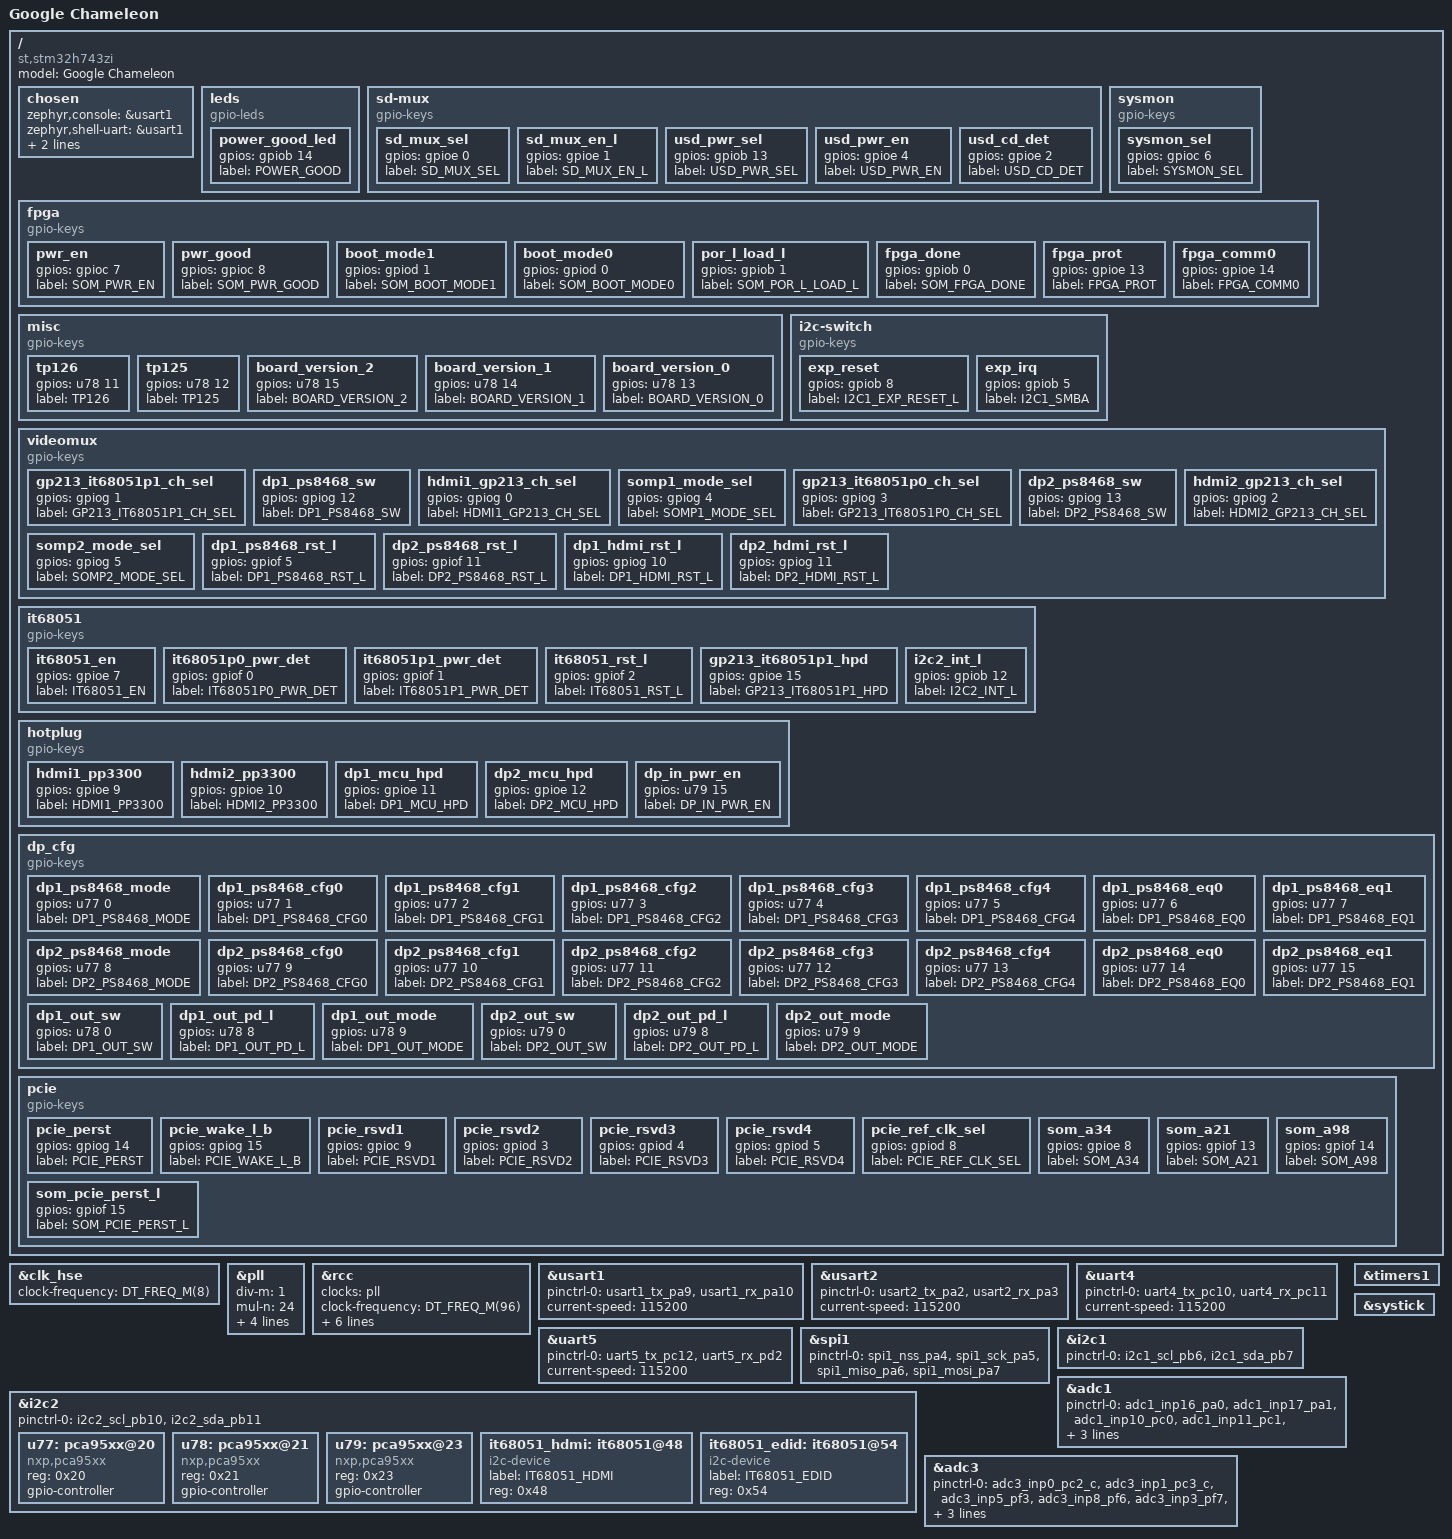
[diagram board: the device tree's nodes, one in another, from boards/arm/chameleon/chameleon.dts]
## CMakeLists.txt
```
# Copyright 2020 The ChromiumOS Authors
# Use of this source code is governed by a BSD-style license that can be
# found in the LICENSE file.
# SPDX-License-Identifier: BSD-3-Clause

cmake_minimum_required(VERSION 3.13.1)
set(BOARD_ROOT ${CMAKE_CURRENT_SOURCE_DIR} CACHE PATH "" FORCE)

if("${ZEPHYR_TOOLCHAIN_VARIANT}" STREQUAL "coreboot-sdk")
include_directories(toolchain/include)
endif()

# Use this copy of Pigweed
get_filename_component(PW_ROOT "${CMAKE_CURRENT_SOURCE_DIR}/../../../../third_party/pigweed" ABSOLUTE)
set(ENV{PW_ROOT} ${PW_ROOT})

set(dir_pw_third_party_nanopb "${CMAKE_CURRENT_SOURCE_DIR}/../../../../third_party/zephyr/nanopb" CACHE PATH "" FORCE)
set(pw_third_party_nanopb_ADD_SUBDIRECTORY ON CACHE BOOL "" FORCE)

list(APPEND ZEPHYR_EXTRA_MODULES
    ${PW_ROOT}
    ${dir_pw_third_party_nanopb}
)

find_package(Zephyr REQUIRED HINTS ${ZEPHYR_BASE})
project(chameleon)

add_definitions(-DCONFIG_RPC_BUFFER_SIZE=1024)
add_definitions(-DPW_LOG_LEVEL=PW_LOG_LEVEL_INFO)
add_definitions(-DPW_LOG_SHOW_MODULE=1)

# Define the proto library
include($ENV{PW_ROOT}/pw_protobuf_compiler/proto.cmake)
pw_proto_library(
    v3.protos
    SOURCES proto/v3.proto
    INPUTS proto/v3.options
)

add_custom_command(OUTPUT version.h
                   COMMAND ${CMAKE_CURRENT_SOURCE_DIR}/getversion.sh
                   WORKING_DIRECTORY ${CMAKE_CURRENT_SOURCE_DIR}/)
add_custom_target(getversion ALL DEPENDS version.h)

FILE(GLOB app_sources src/*.c src/*.cc)
target_include_directories(app PRIVATE include)
target_sources(app PRIVATE ${app_sources} )

zephyr_link_libraries(
    v3.protos.nanopb
    v3.protos.nanopb_rpc
)
```

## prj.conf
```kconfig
# Copyright 2020 The ChromiumOS Authors
# Use of this source code is governed by a BSD-style license that can be
# found in the LICENSE file.
#
# SPDX-License-Identifier: BSD-3-Clause

CONFIG_NEWLIB_LIBC=y
CONFIG_CPP=y
CONFIG_STD_CPP17=y
CONFIG_REQUIRES_FULL_LIBCPP=y

CONFIG_ASSERT=y

CONFIG_CBPRINTF_FP_SUPPORT=y
CONFIG_PRINTK=y
CONFIG_SHELL=y
CONFIG_SHELL_VT100_COLORS=n
CONFIG_SHELL_STATS=n
CONFIG_SHELL_PROMPT_UART="$ "
CONFIG_SHELL_CMD_BUFF_SIZE=1024

CONFIG_SERIAL=y
CONFIG_UART_INTERRUPT_DRIVEN=y
CONFIG_CONSOLE_SUBSYS=y
CONFIG_CONSOLE_GETCHAR=y

CONFIG_LOG=y
CONFIG_LOG_MODE_DEFERRED=y
CONFIG_LOG_SPEED=y
# default to write LOG_LEVEL_INF
CONFIG_LOG_DEFAULT_LEVEL=3

CONFIG_PINCTRL=y

CONFIG_NANOPB=y
CONFIG_PIGWEED_CHECKSUM=y
CONFIG_PIGWEED_HDLC_RPC=y
CONFIG_PIGWEED_ROUTER_PACKET_PARSER=y
CONFIG_PIGWEED_RPC_COMMON=y
CONFIG_PIGWEED_RPC_SERVER=y
CONFIG_PIGWEED_SYS_IO=y
CONFIG_PIGWEED_THREAD_SLEEP=y

# TODO: workaround for b/313926127
CONFIG_BOOT_DELAY=100
```

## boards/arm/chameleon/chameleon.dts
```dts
/* SPDX-License-Identifier: BSD-3-Clause
 *
 * Copyright 2020 The ChromiumOS Authors
 */

/dts-v1/;
#include <st/h7/stm32h743Xi.dtsi>
#include <st/h7/stm32h743zitx-pinctrl.dtsi>

/ {
	model = "Google Chameleon";
	compatible = "st,stm32h743zi", "st,stm32h743";

	chosen {
		zephyr,console = &usart1;
		zephyr,shell-uart = &usart1;
		zephyr,sram = &sram0;
		zephyr,flash = &flash0;
	};

	/*
	 * Note that the GPIO flags (the 0 at the end of the `gpios` tuple)
	 * are ignored by the I/O driver. All flags for GPIOs are specified
	 * in io.c.
	 */
	leds {
		compatible = "gpio-leds";
		power_good_led {
			gpios = <&gpiob 14 0>;
			label = "POWER_GOOD";
		};
	};

	sd-mux {
		compatible = "gpio-keys";

		sd_mux_sel {
			gpios = <&gpioe 0 0>;
			label = "SD_MUX_SEL";
		};

		sd_mux_en_l {
			gpios = <&gpioe 1 0>;
			label = "SD_MUX_EN_L";
		};

		usd_pwr_sel {
			gpios = <&gpiob 13 0>;
			label = "USD_PWR_SEL";
		};

		usd_pwr_en {
			gpios = <&gpioe 4 0>;
			label = "USD_PWR_EN";
		};

		usd_cd_det {
			gpios = <&gpioe 2 0>;
			label = "USD_CD_DET";
		};
	};

	sysmon {
		compatible = "gpio-keys";

		sysmon_sel {
			gpios = <&gpioc 6 0>;
			label = "SYSMON_SEL";
		};
	};

	fpga {
		compatible = "gpio-keys";

		pwr_en {
			gpios = <&gpioc 7 0>;
			label = "SOM_PWR_EN";
		};

		pwr_good {
			gpios = <&gpioc 8 0>;
			label = "SOM_PWR_GOOD";
		};

		boot_mode1 {
			gpios = <&gpiod 1 0>;
			label = "SOM_BOOT_MODE1";
		};

		boot_mode0 {
			gpios = <&gpiod 0 0>;
			label = "SOM_BOOT_MODE0";
		};

		por_l_load_l {
			gpios = <&gpiob 1 0>;
			label = "SOM_POR_L_LOAD_L";
		};

		fpga_done {
			gpios = <&gpiob 0 0>;
			label = "SOM_FPGA_DONE";
		};

		fpga_prot {
			gpios = <&gpioe 13 0>;
			label = "FPGA_PROT";
		};

		fpga_comm0 {
			gpios = <&gpioe 14 0>;
			label = "FPGA_COMM0";
		};
	};

	misc {
		compatible = "gpio-keys";

		tp126 {
			gpios = <&u78 11 0>;
			label = "TP126";
		};

		tp125 {
			gpios = <&u78 12 0>;
			label = "TP125";
		};

		board_version_2 {
			gpios = <&u78 15 0>;
			label = "BOARD_VERSION_2";
		};

		board_version_1 {
			gpios = <&u78 14 0>;
			label = "BOARD_VERSION_1";
		};

		board_version_0 {
			gpios = <&u78 13 0>;
			label = "BOARD_VERSION_0";
		};
	};

	i2c-switch {
		compatible = "gpio-keys";

		exp_reset {
			gpios = <&gpiob 8 0>;
			label = "I2C1_EXP_RESET_L";
		};

		exp_irq {
			gpios = <&gpiob 5 0>;
			label = "I2C1_SMBA";
		};
	};

	videomux {
		compatible = "gpio-keys";

		/*
		 * I/Os are initially set to so that none of the signals are
		 * connected to either the FPGA MGTs or the HDMI Receiver.
		 */
		gp213_it68051p1_ch_sel {
			/* GPU_SEL on U18 */
			gpios = <&gpiog 1 0>;
			label = "GP213_IT68051P1_CH_SEL";
		};

		dp1_ps8468_sw {
			/* SW on U3 */
			gpios = <&gpiog 12 0>;
			label = "DP1_PS8468_SW";
		};

		hdmi1_gp213_ch_sel {
			/* GPU_SEL on U10 */
			gpios = <&gpiog 0 0>;
			label = "HDMI1_GP213_CH_SEL";
		};

		somp1_mode_sel {
			/* GPU_SEL on U11 */
			gpios = <&gpiog 4 0>;
			label = "SOMP1_MODE_SEL";
		};

		/*
		 * Note that all of the channels are designated 1&2 except for
		 * the IT68051, which has ports 1 (channel 1 on the other
		 * switches) and 0 (channel 2 on the other switches).
		 */
		gp213_it68051p0_ch_sel {
			/* GPU_SEL on U31 */
			gpios = <&gpiog 3 0>;
			label = "GP213_IT68051P0_CH_SEL";
		};

		dp2_ps8468_sw {
			/* SW on U22 */
			gpios = <&gpiog 13 0>;
			label = "DP2_PS8468_SW";
		};

		hdmi2_gp213_ch_sel {
			/* GPU_SEL on U29 */
			gpios = <&gpiog 2 0>;
			label = "HDMI2_GP213_CH_SEL";
		};

		somp2_mode_sel {
			/* GPU_SEL on U14 */
			gpios = <&gpiog 5 0>;
			label = "SOMP2_MODE_SEL";
		};

		/*
		 * Reset lines for the PS8468 demuxes.
		 */
		dp1_ps8468_rst_l {
			/* RESETN on U3 */
			gpios = <&gpiof 5 0>;
			label = "DP1_PS8468_RST_L";
		};

		dp2_ps8468_rst_l {
			/* RESETN on U22 */
			gpios = <&gpiof 11 0>;
			label = "DP2_PS8468_RST_L";
		};

		/*
		 * Reset lines for the MCDP2900 DP->HDMI converters.
		 */
		dp1_hdmi_rst_l {
			/* EX_RESETN on U17 */
			gpios = <&gpiog 10 0>;
			label = "DP1_HDMI_RST_L";
		};

		dp2_hdmi_rst_l {
			/* EX_RESETN on U30 */
			gpios = <&gpiog 11 0>;
			label = "DP2_HDMI_RST_L";
		};
	};

	it68051 {
		compatible = "gpio-keys";

		it68051_en {
			gpios = <&gpioe 7 0>;
			label = "IT68051_EN";
		};

		it68051p0_pwr_det {
			gpios = <&gpiof 0 0>;
			label = "IT68051P0_PWR_DET";
		};

		it68051p1_pwr_det {
			gpios = <&gpiof 1 0>;
			label = "IT68051P1_PWR_DET";
		};

		it68051_rst_l {
			gpios = <&gpiof 2 0>;
			label = "IT68051_RST_L";
		};

		gp213_it68051p1_hpd {
			gpios = <&gpioe 15 0>;
			label = "GP213_IT68051P1_HPD";
		};

		i2c2_int_l {
			gpios = <&gpiob 12 0>;
			label = "I2C2_INT_L";
		};
	};

	hotplug {
		compatible = "gpio-keys";

		hdmi1_pp3300 {
			gpios = <&gpioe 9 0>;
			label = "HDMI1_PP3300";
		};

		hdmi2_pp3300 {
			gpios = <&gpioe 10 0>;
			label = "HDMI2_PP3300";
		};

		/*
		 * DP1 and DP2 HPD sense lines. There are two downstream HPD
		 * signals for the PS8468. When either one is asserted, the
		 * PS8468 wakes up and asserts its HPD_SRC. These GPIOs are
		 * connected to HPD_SRC, and let us know that the PS8468 is
		 * awake and we can configure the 8468 over the I2C bus.
		 */
		dp1_mcu_hpd {
			gpios = <&gpioe 11 0>;
			label = "DP1_MCU_HPD";
		};

		dp2_mcu_hpd {
			gpios = <&gpioe 12 0>;
			label = "DP2_MCU_HPD";
		};

		dp_in_pwr_en {
			gpios = <&u79 15 0>;
			label = "DP_IN_PWR_EN";
		};
	};

	dp_cfg {
		compatible = "gpio-keys";

		/*
		 * Most of these are GPIO_INPUT to allow the pull-up/pull-down
		 * resistors to apply the desired level. We only want to actively
		 * drive the MODE pins to select manual mux control by the SW pin.
		 */
		dp1_ps8468_mode {
			gpios = <&u77 0 0>;
			label = "DP1_PS8468_MODE";
		};

		dp1_ps8468_cfg0 {
			gpios = <&u77 1 0>;
			label = "DP1_PS8468_CFG0";
		};

		dp1_ps8468_cfg1 {
			gpios = <&u77 2 0>;
			label = "DP1_PS8468_CFG1";
		};

		dp1_ps8468_cfg2 {
			gpios = <&u77 3 0>;
			label = "DP1_PS8468_CFG2";
		};

		dp1_ps8468_cfg3 {
			gpios = <&u77 4 0>;
			label = "DP1_PS8468_CFG3";
		};

		dp1_ps8468_cfg4 {
			gpios = <&u77 5 0>;
			label = "DP1_PS8468_CFG4";
		};

		dp1_ps8468_eq0  {
			gpios = <&u77 6 0>;
			label = "DP1_PS8468_EQ0";
		};

		dp1_ps8468_eq1  {
			gpios = <&u77 7 0>;
			label = "DP1_PS8468_EQ1";
		};

		dp2_ps8468_mode {
			gpios = <&u77 8 0>;
			label = "DP2_PS8468_MODE";
		};

		dp2_ps8468_cfg0 {
			gpios = <&u77 9 0>;
			label = "DP2_PS8468_CFG0";
		};

		dp2_ps8468_cfg1 {
			gpios = <&u77 10 0>;
			label = "DP2_PS8468_CFG1";
		};

		dp2_ps8468_cfg2 {
			gpios = <&u77 11 0>;
			label = "DP2_PS8468_CFG2";
		};

		dp2_ps8468_cfg3 {
			gpios = <&u77 12 0>;
			label = "DP2_PS8468_CFG3";
		};

		dp2_ps8468_cfg4 {
			gpios = <&u77 13 0>;
			label = "DP2_PS8468_CFG4";
		};

		dp2_ps8468_eq0  {
			gpios = <&u77 14 0>;
			label = "DP2_PS8468_EQ0";
		};

		dp2_ps8468_eq1  {
			gpios = <&u77 15 0>;
			label = "DP2_PS8468_EQ1";
		};

		dp1_out_sw {
			gpios = <&u78 0 0>;
			label = "DP1_OUT_SW";
		};

		dp1_out_pd_l {
			gpios = <&u78 8 0>;
			label = "DP1_OUT_PD_L";
		};

		dp1_out_mode {
			gpios = <&u78 9 0>;
			label = "DP1_OUT_MODE";
		};

		dp2_out_sw {
			gpios = <&u79 0 0>;
			label = "DP2_OUT_SW";
		};

		dp2_out_pd_l {
			gpios = <&u79 8 0>;
			label = "DP2_OUT_PD_L";
		};

		dp2_out_mode {
			gpios = <&u79 9 0>;
			label = "DP2_OUT_MODE";
		};
	};

	pcie {
		compatible = "gpio-keys";

		pcie_perst {
			gpios = <&gpiog 14 0>;
			label = "PCIE_PERST";
		};

		pcie_wake_l_b {
			gpios = <&gpiog 15 0>;
			label = "PCIE_WAKE_L_B";
		};

		pcie_rsvd1 {
			gpios = <&gpioc 9 0>;
			label = "PCIE_RSVD1";
		};

		pcie_rsvd2 {
			gpios = <&gpiod 3 0>;
			label = "PCIE_RSVD2";
		};

		pcie_rsvd3 {
			gpios = <&gpiod 4 0>;
			label = "PCIE_RSVD3";
		};

		pcie_rsvd4 {
			gpios = <&gpiod 5 0>;
			label = "PCIE_RSVD4";
		};

		pcie_ref_clk_sel {
			gpios = <&gpiod 8 0>;
			label = "PCIE_REF_CLK_SEL";
		};

		som_a34 {
			gpios = <&gpioe 8 0>;
			label = "SOM_A34";
		};

		som_a21 {
			gpios = <&gpiof 13 0>;
			label = "SOM_A21";
		};

		som_a98 {
			gpios = <&gpiof 14 0>;
			label = "SOM_A98";
		};

		som_pcie_perst_l {
			gpios = <&gpiof 15 0>;
			label = "SOM_PCIE_PERST_L";
		};
	};
};

&clk_hse {
	clock-frequency = <DT_FREQ_M(8)>;
	status = "okay";
};

&pll {
	div-m = <1>;
	mul-n = <24>;
	div-p = <2>;
	div-q = <4>;
	div-r = <2>;
	clocks = <&clk_hse>;
	status = "okay";
};

&rcc {
	clocks = <&pll>;
	clock-frequency = <DT_FREQ_M(96)>;
	d1cpre = <1>;
	hpre = <1>;
	d1ppre = <2>;
	d2ppre1 = <2>;
	d2ppre2 = <2>;
	d3ppre = <2>;
};

&usart1 {
	pinctrl-0 = <&usart1_tx_pa9 &usart1_rx_pa10>;
	pinctrl-names = "default";
	current-speed = <115200>;
	status = "okay";
};

&usart2 {
	pinctrl-0 = <&usart2_tx_pa2 &usart2_rx_pa3>;
	pinctrl-names = "default";
	current-speed = <115200>;
	status = "okay";
};

&uart4 {
	pinctrl-0 = <&uart4_tx_pc10 &uart4_rx_pc11>;
	pinctrl-names = "default";
	current-speed = <115200>;
	status = "okay";
};

&uart5 {
	pinctrl-0 = <&uart5_tx_pc12 &uart5_rx_pd2>;
	pinctrl-names = "default";
	current-speed = <115200>;
	status = "okay";
};

&spi1 {
	pinctrl-0 = <&spi1_nss_pa4 &spi1_sck_pa5 &spi1_miso_pa6 &spi1_mosi_pa7>;
	pinctrl-names = "default";
	status = "okay";
};

&i2c1 {
	pinctrl-0 = <&i2c1_scl_pb6 &i2c1_sda_pb7>;
	pinctrl-names = "default";
	status = "okay";
};

&i2c2 {
	pinctrl-0 = <&i2c2_scl_pb10 &i2c2_sda_pb11>;
	pinctrl-names = "default";
	status = "okay";

	/* U77 I/O expander, config signals for PS8468 */
	u77: pca95xx@20 {
		compatible = "nxp,pca95xx";
		reg = <0x20>;
		#gpio-cells = <2>;
		gpio-controller;
	};

	/* U78 I/O expander, DP1 OUT config signals, plus misc I/O */
	u78: pca95xx@21 {
		compatible = "nxp,pca95xx";
		reg = <0x21>;
		#gpio-cells = <2>;
		gpio-controller;
	};

	/* U79 I/O expander DP2 OUT config, HDMI input reset, DP IN power */
	u79: pca95xx@23 {
		compatible = "nxp,pca95xx";
		reg = <0x23>;
		#gpio-cells = <2>;
		gpio-controller;
	};

	/* I2C address for the IT68051
	 *
	 * Note that the IT68051 documentation uses 8-bit addresses
	 * (ITE docs say that the HDMI block is address 0x90) but all of
	 * our code uses 7-bit addresses.
	 */
	it68051_hdmi: it68051@48 {
		compatible = "i2c-device";
		label = "IT68051_HDMI";
		reg = <0x48>;
	};

	it68051_edid: it68051@54 {
		compatible = "i2c-device";
		label = "IT68051_EDID";
		reg = <0x54>;
	};
};

&adc1 {
	pinctrl-0 = <&adc1_inp16_pa0 &adc1_inp17_pa1 &adc1_inp10_pc0
		     &adc1_inp11_pc1 &adc1_inp4_pc4 &adc1_inp8_pc5
		     &adc1_inp6_pf12>;
	pinctrl-names = "default";
	status = "okay";
	st,adc-clock-source = <SYNC>;
	st,adc-prescaler = <4>; /* 96MHz AHB / 4 = 24MHz */
};

&adc3 {
	/* These ADC inputs are only available on ADC3 */
	pinctrl-0 = <&adc3_inp0_pc2_c &adc3_inp1_pc3_c &adc3_inp5_pf3
		     &adc3_inp8_pf6 &adc3_inp3_pf7 &adc3_inp7_pf8
		     &adc3_inp2_pf9 &adc3_inp6_pf10>;
	pinctrl-names = "default";
	status = "okay";
	st,adc-clock-source = <SYNC>;
	st,adc-prescaler = <4>; /* 96MHz AHB / 4 = 24MHz */
};

&timers1 {
	status = "okay";
};

&systick {
	status = "okay";
};
```

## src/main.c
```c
/* SPDX-License-Identifier: BSD-3-Clause
 *
 * Copyright 2020 The ChromiumOS Authors
 * Use of this source code is governed by a BSD-style license that can be
 * found in the LICENSE file.
 */

#include <zephyr/kernel.h>
#include <zephyr/logging/log.h>

#include "io.h"

LOG_MODULE_REGISTER(main);

void main(void)
{
	int ret;

	ret = gpio_set_level(power_good_led, 1);
	if (ret < 0) {
		LOG_ERR("Failed to turn on POWER_GOOD, ret = %d.\n", ret);
	}
}
```

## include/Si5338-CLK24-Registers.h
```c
//Register map for use with AN428 (JumpStart)
//http://www.silabs.com/clocks
//#BEGIN_HEADER
//Date = Monday, January 10, 2022 5:41 PM
//File version = 3
//Software Name = ClockBuilder Pro
//Software version = 2.45.0.0
//Software date = 7 16, 2020
//Chip = Si533x
//Part Number = Si533x
//#END_HEADER
//Input Frequency (MHz) = 24.000000000
//Input Type = CMOS_SSTL_HSTL
//P1 = 1
//Input Mux = RefClk
//FDBK Input Frequency (MHz) = 24.000000000
//FDBK Input Type = OFF
//P2 = 1
//FDBK Mux = NoClk
//PFD Input Frequency (MHz) = 24.000000000
//VCO Frequency (GHz) = 2.700000
//N = 112  1/2  (112.5000)
//Internal feedback enabled
//Output Clock 0
// Output Frequency (MHz) = 100.000000000
// Mux Selection = IDn
// MultiSynth = 27  (27.0000)
// R = 1
//Output Clock 1
// Output Frequency (MHz) = 100.000000000
// Mux Selection = IDn
// MultiSynth = 27  (27.0000)
// R = 1
//Output Clock 2
// Output Frequency (MHz) = 100.000000000
// Mux Selection = IDn
// MultiSynth = 27  (27.0000)
// R = 1
//Output Clock 3
// Output Frequency (MHz) = 135.000000000
// Mux Selection = IDn
// MultiSynth = 20  (20.0000)
// R = 1
//Driver 0
// Enabled
// Powered on
// Output voltage = 3.30
// Output type = 3.3V LVDS
// Output state when disabled = AlwaysOn
//Driver 1
// Enabled
// Powered on
// Output voltage = 3.30
// Output type = 3.3V LVDS
// Output state when disabled = AlwaysOn
//Driver 2
// Enabled
// Powered on
// Output voltage = 1.80
// Output type = 1.8V CMOS on A
// Output state when disabled = AlwaysOn
//Driver 3
// Enabled
// Powered on
// Output voltage = 3.30
// Output type = 3.3V LVDS
// Output state when disabled = AlwaysOn
//Clock 0 phase inc/dec step size (ns) = 0.000
//Clock 1 phase inc/dec step size (ns) = 0.000
//Clock 2 phase inc/dec step size (ns) = 0.000
//Clock 3 phase inc/dec step size (ns) = 0.000
//Phase increment and decrement pin control is off
//Frequency increment and decrement pin control is off
//Frequency increment and decrement is disabled
//Initial phase offset 0 (ns) = 0.000
//Initial phase offset 1 (ns) = 0.000
//Initial phase offset 2 (ns) = 0.000
//Initial phase offset 3 (ns) = 0.000
//SSC is disabled

#ifdef __cplusplus
extern "C" {
#endif

#define NUM_REGS_MAX 350

typedef struct Reg_Data{
   unsigned char Reg_Addr;
   unsigned char Reg_Val;
   unsigned char Reg_Mask;
} Reg_Data;

Reg_Data const code Reg_Store[NUM_REGS_MAX] = {
{  0,0x00,0x00},
{  1,0x00,0x00},
{  2,0x00,0x00},
{  3,0x00,0x00},
{  4,0x00,0x00},
{  5,0x00,0x00},
{  6,0x00,0x1D},
{  7,0x00,0x00},
{  8,0x70,0x00},
{  9,0x0F,0x00},
{ 10,0x00,0x00},
{ 11,0x00,0x00},
{ 12,0x00,0x00},
{ 13,0x00,0x00},
{ 14,0x00,0x00},
{ 15,0x00,0x00},
{ 16,0x00,0x00},
{ 17,0x00,0x00},
{ 18,0x00,0x00},
{ 19,0x00,0x00},
{ 20,0x00,0x00},
{ 21,0x00,0x00},
{ 22,0x00,0x00},
{ 23,0x00,0x00},
{ 24,0x00,0x00},
{ 25,0x00,0x00},
{ 26,0x00,0x00},
{ 27,0x70,0x80},
{ 28,0x0B,0xFF},
{ 29,0x08,0xFF},
{ 30,0xB0,0xFF},
{ 31,0xC0,0xFF},
{ 32,0xC0,0xFF},
{ 33,0xC0,0xFF},
{ 34,0xC0,0xFF},
{ 35,0x20,0xFF},
{ 36,0x06,0x1F},
{ 37,0x06,0x1F},
{ 38,0x01,0x1F},
{ 39,0x06,0x1F},
{ 40,0x63,0xFF},
{ 41,0x54,0x7F},
{ 42,0x23,0x3F},
{ 43,0x00,0x00},
{ 44,0x00,0x00},
{ 45,0x00,0xFF},
{ 46,0x00,0xFF},
{ 47,0x14,0x3F},
{ 48,0x34,0xFF},
{ 49,0x00,0xFF},
{ 50,0xC3,0xFF},
{ 51,0x07,0xFF},
{ 52,0x10,0xFF},
{ 53,0x80,0xFF},
{ 54,0x0B,0xFF},
{ 55,0x00,0xFF},
{ 56,0x00,0xFF},
{ 57,0x00,0xFF},
{ 58,0x00,0xFF},
{ 59,0x01,0xFF},
{ 60,0x00,0xFF},
{ 61,0x00,0xFF},
{ 62,0x00,0x3F},
{ 63,0x10,0xFF},
{ 64,0x80,0xFF},
{ 65,0x0B,0xFF},
{ 66,0x00,0xFF},
{ 67,0x00,0xFF},
{ 68,0x00,0xFF},
{ 69,0x00,0xFF},
{ 70,0x01,0xFF},
{ 71,0x00,0xFF},
{ 72,0x00,0xFF},
{ 73,0x00,0x3F},
{ 74,0x10,0xFF},
{ 75,0x80,0xFF},
{ 76,0x0B,0xFF},
{ 77,0x00,0xFF},
{ 78,0x00,0xFF},
{ 79,0x00,0xFF},
{ 80,0x00,0xFF},
{ 81,0x01,0xFF},
{ 82,0x00,0xFF},
{ 83,0x00,0xFF},
{ 84,0x00,0x3F},
{ 85,0x10,0xFF},
{ 86,0x00,0xFF},
{ 87,0x08,0xFF},
{ 88,0x00,0xFF},
{ 89,0x00,0xFF},
{ 90,0x00,0xFF},
{ 91,0x00,0xFF},
{ 92,0x01,0xFF},
{ 93,0x00,0xFF},
{ 94,0x00,0xFF},
{ 95,0x00,0x3F},
{ 96,0x10,0x00},
{ 97,0x40,0xFF},
{ 98,0x36,0xFF},
{ 99,0x00,0xFF},
{100,0x00,0xFF},
{101,0x00,0xFF},
{102,0x00,0xFF},
{103,0x02,0xFF},
{104,0x00,0xFF},
{105,0x00,0xFF},
{106,0x80,0xBF},
{107,0x00,0xFF},
{108,0x00,0xFF},
{109,0x00,0xFF},
{110,0xC0,0xFF},
{111,0x00,0xFF},
{112,0x00,0xFF},
{113,0x00,0xFF},
{114,0xC0,0xFF},
{115,0x00,0xFF},
{116,0x80,0xFF},
{117,0x00,0xFF},
{118,0xC0,0xFF},
{119,0x00,0xFF},
{120,0x00,0xFF},
{121,0x00,0xFF},
{122,0xC0,0xFF},
{123,0x00,0xFF},
{124,0x00,0xFF},
{125,0x00,0xFF},
{126,0x00,0xFF},
{127,0x00,0xFF},
{128,0x00,0xFF},
{129,0x00,0x0F},
{130,0x00,0x0F},
{131,0x00,0xFF},
{132,0x00,0xFF},
{133,0x00,0xFF},
{134,0x00,0xFF},
{135,0x00,0xFF},
{136,0x00,0xFF},
{137,0x00,0xFF},
{138,0x00,0xFF},
{139,0x00,0xFF},
{140,0x00,0xFF},
{141,0x00,0xFF},
{142,0x00,0xFF},
{143,0x00,0xFF},
{144,0x00,0xFF},
{145,0x00,0x00},
{146,0xFF,0x00},
{147,0x00,0x00},
{148,0x00,0x00},
{149,0x00,0x00},
{150,0x00,0x00},
{151,0x00,0x00},
{152,0x00,0xFF},
{153,0x00,0xFF},
{154,0x00,0xFF},
{155,0x00,0xFF},
{156,0x00,0xFF},
{157,0x00,0xFF},
{158,0x00,0x0F},
{159,0x00,0x0F},
{160,0x00,0xFF},
{161,0x00,0xFF},
{162,0x00,0xFF},
{163,0x00,0xFF},
{164,0x00,0xFF},
{165,0x00,0xFF},
{166,0x00,0xFF},
{167,0x00,0xFF},
{168,0x00,0xFF},
{169,0x00,0xFF},
{170,0x00,0xFF},
{171,0x00,0xFF},
{172,0x00,0xFF},
{173,0x00,0xFF},
{174,0x00,0xFF},
{175,0x00,0xFF},
{176,0x00,0xFF},
{177,0x00,0xFF},
{178,0x00,0xFF},
{179,0x00,0xFF},
{180,0x00,0xFF},
{181,0x00,0x0F},
{182,0x00,0xFF},
{183,0x00,0xFF},
{184,0x00,0xFF},
{185,0x00,0xFF},
{186,0x00,0xFF},
{187,0x00,0xFF},
{188,0x00,0xFF},
{189,0x00,0xFF},
{190,0x00,0xFF},
{191,0x00,0xFF},
{192,0x00,0xFF},
{193,0x00,0xFF},
{194,0x00,0xFF},
{195,0x00,0xFF},
{196,0x00,0xFF},
{197,0x00,0xFF},
{198,0x00,0xFF},
{199,0x00,0xFF},
{200,0x00,0xFF},
{201,0x00,0xFF},
{202,0x00,0xFF},
{203,0x00,0x0F},
{204,0x00,0xFF},
{205,0x00,0xFF},
{206,0x00,0xFF},
{207,0x00,0xFF},
{208,0x00,0xFF},
{209,0x00,0xFF},
{210,0x00,0xFF},
{211,0x00,0xFF},
{212,0x00,0xFF},
{213,0x00,0xFF},
{214,0x00,0xFF},
{215,0x00,0xFF},
{216,0x00,0xFF},
{217,0x00,0xFF},
{218,0x00,0x00},
{219,0x00,0x00},
{220,0x00,0x00},
{221,0x0D,0x00},
{222,0x00,0x00},
{223,0x00,0x00},
{224,0xF4,0x00},
{225,0xF0,0x00},
{226,0x00,0x00},
{227,0x00,0x00},
{228,0x00,0x00},
{229,0x00,0x00},
{231,0x00,0x00},
{232,0x00,0x00},
{233,0x00,0x00},
{234,0x00,0x00},
{235,0x00,0x00},
{236,0x00,0x00},
{237,0x00,0x00},
{238,0x14,0x00},
{239,0x00,0x00},
{240,0x00,0x00},
{242,0x02,0x02},
{243,0xF0,0x00},
{244,0x00,0x00},
{245,0x00,0x00},
{247,0x00,0x00},
{248,0x00,0x00},
{249,0xA8,0x00},
{250,0x00,0x00},
{251,0x84,0x00},
{252,0x00,0x00},
{253,0x00,0x00},
{254,0x00,0x00},
{255, 1, 0xFF}, // set page bit to 1
{  0,0x00,0x00},
{  1,0x00,0x00},
{  2,0x00,0x00},
{  3,0x00,0x00},
{  4,0x00,0x00},
{  5,0x00,0x00},
{  6,0x00,0x00},
{  7,0x00,0x00},
{  8,0x00,0x00},
{  9,0x00,0x00},
{ 10,0x00,0x00},
{ 11,0x00,0x00},
{ 12,0x00,0x00},
{ 13,0x00,0x00},
{ 14,0x00,0x00},
{ 15,0x00,0x00},
{ 16,0x00,0x00},
{ 17,0x01,0x00},
{ 18,0x00,0x00},
{ 19,0x00,0x00},
{ 20,0x90,0x00},
{ 21,0x31,0x00},
{ 22,0x00,0x00},
{ 23,0x00,0x00},
{ 24,0x01,0x00},
{ 25,0x00,0x00},
{ 26,0x00,0x00},
{ 27,0x00,0x00},
{ 28,0x00,0x00},
{ 29,0x00,0x00},
{ 30,0x00,0x00},
{ 31,0x00,0xFF},
{ 32,0x00,0xFF},
{ 33,0x01,0xFF},
{ 34,0x00,0xFF},
{ 35,0x00,0xFF},
{ 36,0x90,0xFF},
{ 37,0x31,0xFF},
{ 38,0x00,0xFF},
{ 39,0x00,0xFF},
{ 40,0x01,0xFF},
{ 41,0x00,0xFF},
{ 42,0x00,0xFF},
{ 43,0x00,0x0F},
{ 44,0x00,0x00},
{ 45,0x00,0x00},
{ 46,0x00,0x00},
{ 47,0x00,0xFF},
{ 48,0x00,0xFF},
{ 49,0x01,0xFF},
{ 50,0x00,0xFF},
{ 51,0x00,0xFF},
{ 52,0x90,0xFF},
{ 53,0x31,0xFF},
{ 54,0x00,0xFF},
{ 55,0x00,0xFF},
{ 56,0x01,0xFF},
{ 57,0x00,0xFF},
{ 58,0x00,0xFF},
{ 59,0x00,0x0F},
{ 60,0x00,0x00},
{ 61,0x00,0x00},
{ 62,0x00,0x00},
{ 63,0x00,0xFF},
{ 64,0x00,0xFF},
{ 65,0x01,0xFF},
{ 66,0x00,0xFF},
{ 67,0x00,0xFF},
{ 68,0x90,0xFF},
{ 69,0x31,0xFF},
{ 70,0x00,0xFF},
{ 71,0x00,0xFF},
{ 72,0x01,0xFF},
{ 73,0x00,0xFF},
{ 74,0x00,0xFF},
{ 75,0x00,0x0F},
{ 76,0x00,0x00},
{ 77,0x00,0x00},
{ 78,0x00,0x00},
{ 79,0x00,0xFF},
{ 80,0x00,0xFF},
{ 81,0x00,0xFF},
{ 82,0x00,0xFF},
{ 83,0x00,0xFF},
{ 84,0x90,0xFF},
{ 85,0x31,0xFF},
{ 86,0x00,0xFF},
{ 87,0x00,0xFF},
{ 88,0x01,0xFF},
{ 89,0x00,0xFF},
{ 90,0x00,0xFF},
{ 91,0x00,0x0F},
{ 92,0x00,0x00},
{ 93,0x00,0x00},
{ 94,0x00,0x00},
{255, 0, 0xFF} }; // set page bit to 0
//End of file

#ifdef __cplusplus
}
#endif
```

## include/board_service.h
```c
/* SPDX-License-Identifier: BSD-3-Clause
 *
 * Copyright 2021 The ChromiumOS Authors
 * Use of this source code is governed by a BSD-style license that can be
 * found in the LICENSE file.
 *
 * Copied from the implementation stubs section of
 * build/v3.protos/nanopb_rpc/proto/v3.rpc.pb.h
 */

#ifndef __BOARD_SERVICE_H
#define __BOARD_SERVICE_H

#include "proto/v3.rpc.pb.h"

// Implementation class for board_service.
class board_service : public pw_rpc::nanopb::board_service::Service<board_service> {
 public:
  ::pw::Status get_board_version( const ::Empty& request, ::board_service_version_response& response);

  ::pw::Status get_sysmon( const ::Empty& request, ::sysmon_response& response);

  ::pw::Status get_source_presence( const ::Empty& request, ::source_presence_response& response);

  ::pw::Status get_code_version( const ::Empty& request, ::board_service_code_version_response& response);
};

#endif
```

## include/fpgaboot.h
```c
/* SPDX-License-Identifier: BSD-3-Clause
 *
 * Copyright 2020 The ChromiumOS Authors
 * Use of this source code is governed by a BSD-style license that can be
 * found in the LICENSE file.
 */

#ifndef __FPGABOOT_H
#define __FPGABOOT_H

#include <zephyr/kernel.h>

#ifdef __cplusplus
extern "C" {
#endif

/**
 * Define the boot source for the FPGA
 *
 * The Enclustra FPGA SOM (system-on-module) defines two pins, BOOT_MODE[1:0]
 * to control the boot source for the FPGA. The module includes an EMMC
 * flash (essentially an SD card in an IC package), and a quad-SPI flash
 * memory. The module also has SDIO signals that the carrier board can
 * route to an SD/microSD socket (which Chameleon v3 does).
 *
 * @note The default boot mode on Chameleon v3 is SDIO.
 */
enum fpga_boot_mode { FPGA_BOOT_EMMC, FPGA_BOOT_QSPI, FPGA_BOOT_SDIO };

/*
 * @brief Set the boot mode for the FPGA SOM
 *
 * @param mode One of the `fpga_boot_mode` values
 * @retval 0
 * No errors.
 * @retval -EINVAL
 * Invalid value, probably from passing an int instead of enum
 */
int fpgaboot_set_boot_mode(enum fpga_boot_mode mode);

/*
 * @brief Send a request to power on
 *
 * @note The caller should call `fpgaboot_set_boot_mode` before this unless
 * they want to use the default value (which is `FPGA_BOOT_SDIO`)
 *
 * @retval 0
 * No errors.
 * @retval -ENOMSG
 * Message was not posted.
 * @retval -EAGAIN
 * Waiting period timed out.
 */
int fpgaboot_power_on(void);

/*
 * @brief Send a request to power off
 *
 * @retval 0
 * No errors.
 * @retval -ENOMSG
 * Message was not posted.
 * @retval -EAGAIN
 * Waiting period timed out.
 */
int fpgaboot_power_off(void);

#ifdef __cplusplus
}
#endif

#endif
```

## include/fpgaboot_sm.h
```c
/* SPDX-License-Identifier: BSD-3-Clause
 *
 * Copyright 2020 The ChromiumOS Authors
 * Use of this source code is governed by a BSD-style license that can be
 * found in the LICENSE file.
 *
 * Implement a state machine for powering on, booting, and powering off the
 * FPGA System-on-Module (SOM) that is the heart of Chameleon v3.
 * See doc/fpga_sm.md for design details.
 */

#ifndef __FPGABOOT_SM_H
#define __FPGABOOT_SM_H

#include <stdbool.h>
#include <zephyr/kernel.h>

#ifdef __cplusplus
extern "C" {
#endif

enum fpga_state {
	FPGABOOT_OFF,
	FPGABOOT_PWR_GOOD,
	FPGABOOT_LOAD,
	FPGABOOT_RUNNING,
};

enum fpga_event {
	FPGABOOT_EVENT_NONE,
	FPGABOOT_POWER_ON_REQ,
	FPGABOOT_POWER_OFF_REQ,
	FPGABOOT_SOM_PWR_GOOD_ASSERTED,
	FPGABOOT_SOM_PWR_GOOD_DEASSERTED,
	FPGABOOT_SOM_FPGA_DONE_ASSERTED,
	FPGABOOT_SOM_FPGA_DONE_DEASSERTED,
	FPGABOOT_TIMER_EXPIRED,
};

#define FPGABOOT_ACTION_NONE 0x00
#define FPGABOOT_ASSERT_SOM_PWR_EN 0x01
#define FPGABOOT_DEASSERT_SOM_PWR_EN 0x02
/* NB: SOM_POR_L_LOAD_L is active low, so "assert" == "set to 0V" */
#define FPGABOOT_ASSERT_SOM_POR_L_LOAD_L 0x04
#define FPGABOOT_DEASSERT_SOM_POR_L_LOAD_L 0x08
#define FPGABOOT_START_SHORT_TIMER 0x10
#define FPGABOOT_START_LONG_TIMER 0x20
#define FPGABOOT_STOP_TIMER 0x40

/**
 * @brief Initialize the state machine data
 *
 * Uses the values of `PWR_EN`, `PWR_GOOD`, and `FPGA_DONE` to determine
 * which state it should go to.
 *
 * @param pwr_en
 * @param pwr_good
 * @param fpga_done
 * @param p_state pointer to an `fpga_state` variable
 * @param[out] p_actions pointer to variable to set bit flags for actions.
 */
void fpgaboot_init_state_machine(int pwr_en, int pwr_good, int fpga_done,
                                 enum fpga_state *p_state, uint32_t *p_actions);

/**
 * @brief Run the state machine
 *
 * The caller should set `event` to indicate the event being processed.
 * The state machine may change `*p_state` and set one or more bits in
 * `*p_actions` to indicate what the caller should do next.
 *
 * @param event the event being processed
 * @param[inout] p_state pointer to an `fpga_state` variable
 * @param[out] p_actions pointer to variable to set bit flags for actions.
 */
void fpgaboot_run_state_machine(enum fpga_event event, enum fpga_state *p_state,
				uint32_t *p_actions);

/**
 * @brief Determine if the FPGA is in a steady state, on or off
 *
 * @param state an `fpga_state` variable
 * @retval true
 * if the FPGA is either on or off
 * @retval false
 * if the FPGA is in a different state moving towards either on or off
 */
bool fpgaboot_is_steady_state(enum fpga_state state);

#ifdef __cplusplus
}
#endif

#endif
```

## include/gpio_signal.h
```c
/* SPDX-License-Identifier: BSD-3-Clause
 *
 * Copyright 2020 The Chromium OS Authors. All rights reserved.
 * Use of this source code is governed by a BSD-style license that can be
 * found in the LICENSE file.
 */

#ifndef __GPIO_SIGNAL_H
#define __GPIO_SIGNAL_H

#include <zephyr.h>
#include <device.h>
#include <devicetree.h>
#include <init.h>
#include <drivers/gpio.h>

#define GPIO_PIN_WITH_COMMA(path) DT_GPIO_PIN(path, gpios),

#define GPIO_FLAGS_WITH_COMMA(path) DT_GPIO_FLAGS(path, gpios),

#define NULL_WITH_COMMA(path) NULL,

#define GPIO_DEV_NAME_WITH_COMMA(path) DT_GPIO_LABEL(path, gpios),

#define GPIO_ENUM(path) DT_CAT(GPIO_, path)
#define GPIO_ENUM_WITH_COMMA(path) GPIO_ENUM(path),

#define DECLARE_GPIOS_FOR(path)                                               \
	static const gpio_pin_t gpio_pins[] = { DT_FOREACH_CHILD(             \
		DT_PATH(path), GPIO_PIN_WITH_COMMA) };                        \
	static const int gpio_flags[] = { DT_FOREACH_CHILD(                   \
		DT_PATH(path), GPIO_FLAGS_WITH_COMMA) };                      \
	static const struct device *gpio_devs[] = { DT_FOREACH_CHILD(         \
		DT_PATH(path), NULL_WITH_COMMA) };                            \
	static const char *const gpio_dev_names[] = { DT_FOREACH_CHILD(       \
		DT_PATH(path), GPIO_DEV_NAME_WITH_COMMA) };                   \
	enum { DT_FOREACH_CHILD(DT_PATH(path), GPIO_ENUM_WITH_COMMA) };       \
	static int local_init_devices_for_##path(const struct device *ptr)    \
	{                                                                     \
		ARG_UNUSED(ptr);                                              \
		for (int idx = 0; idx < ARRAY_SIZE(gpio_devs); ++idx) {       \
			gpio_devs[idx] =                                      \
				device_get_binding(gpio_dev_names[idx]);      \
			if (!gpio_devs[idx]) {                                \
				printk("local_init_devices_for_%s: "          \
				       "device_get_binding(%s) failed!\n",    \
				       #path, gpio_dev_names[idx]);           \
				continue;                                     \
			}                                                     \
			int ret = gpio_pin_configure(gpio_devs[idx],          \
						     gpio_pins[idx],          \
						     gpio_flags[idx]);        \
			if (ret != 0) {                                       \
				printk("local_init_devices_for_%s: "          \
				       "gpio_pin_configure(%s, %d, %d) "      \
				       "failed, ret = %d\n",                  \
				       #path, gpio_dev_names[idx],            \
				       gpio_pins[idx], gpio_flags[idx], ret); \
				continue;                                     \
			}                                                     \
		}                                                             \
		return 0;                                                     \
	}                                                                     \
	SYS_INIT(local_init_devices_for_##path, APPLICATION, 1);

#define GPIO_LOOKUP_COMMON(path) \
	gpio_devs[GPIO_ENUM(path)], gpio_pins[GPIO_ENUM(path)]
#define GPIO_LOOKUP(...) GPIO_LOOKUP_COMMON(DT_PATH(__VA_ARGS__))

/*
 * In your C file, include this header and declare the GPIOs based on the
 * devicetree node.
 *
 *  #include "gpio_signal.h"
 *  DECLARE_GPIOS_FOR(sd_mux);
 *
 * This macro declares some static const arrays and a local function (called
 * from SYS_INIT) that will initialize all of the GPIOs.
 *
 * Use `GPIO_LOOKUP(sd_mux, sd_mux_sel)` anywhere you need a `struct device*`
 * and a `gpio_pin_t` together:
 *
 *  gpio_pin_set(GPIO_LOOKUP(sd_mux, sd_mux_sel), value);
 *  gpio_pin_get(GPIO_LOOKUP(sd_mux, sd_mux_sel));
 *
 * Use `GPIO_ENUM(DT_PATH(...))` if you need the `struct device*` or the
 * `gpio_pin_t` separately, such as for setting up interrupt handlers:
 *
 *  gpio_init_callback(&pwr_good_cb_data, pwr_good_cb,
 *                     BIT(gpio_pins[GPIO_ENUM(DT_PATH(fpga, pwr_good))]));
 *  gpio_add_callback(gpio_devs[GPIO_ENUM(DT_PATH(fpga, pwr_good))],
 *                    &pwr_good_cb_data);
 *
 */

#endif
```

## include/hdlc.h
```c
/* SPDX-License-Identifier: BSD-3-Clause
 *
 * Copyright 2023 The ChromiumOS Authors
 * Use of this source code is governed by a BSD-style license that can be
 * found in the LICENSE file.
 */

#ifndef __HDLC_H
#define __HDLC_H

#include <zephyr/kernel.h>
#include <zephyr/drivers/uart.h>
#include <zephyr/logging/log.h>

#include "pw_hdlc/rpc_channel.h"
#include "pw_rpc/server.h"
#include "pw_status/status.h"
#include "pw_stream/sys_io_stream.h"

extern pw::stream::SysIoWriter hdlc_writer;
extern k_mutex hdlc_uart_mutex;

#endif /* __HDLC_H */
```

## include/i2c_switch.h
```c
/* SPDX-License-Identifier: BSD-3-Clause
 *
 * Copyright 2020 The ChromiumOS Authors
 * Use of this source code is governed by a BSD-style license that can be
 * found in the LICENSE file.
 */

#ifndef __I2C_SWITCH_H
#define __I2C_SWITCH_H

#include <zephyr/kernel.h>

#ifdef __cplusplus
extern "C" {
#endif

enum i2c_switch_reset_value {
	RESET_ASSERTED = 0,
	RESET_DEASSERTED
};

/**
 * @brief Select which bus is enabled
 *
 * The I2C switch controls access to 4 secondary buses. Any task that sets
 * the switch to enable a secondary bus expects to have exclusive access
 * to the bus until it's done. Allowing another task to come along and change
 * the switch to enable a different bus will cause problems. So ... setting
 * the switch to enable a secondary bus will also lock a mutex (or wait for
 * the mutex if it's already locked). Setting the switch to "disabled" will
 * unlock the mutex.
 *
 * @param bus bus number, 0-3, of which bus to enable. Any number <0 or >3
 * will disable all buses.
 *
 * @retval 0 if successful.
 * @retval -ENODEV or error return from Zephyr API functions.
 */
int i2c_switch_select_bus(int bus);

/**
 * @brief Control the reset pin on the i2c switch.
 *
 * @param val one of enum i2c_switch_reset_value to assert or deassert the
 * reset pin
 *
 * @retval 0 if successful.
 * @retval -ENODEV or error return from Zephyr API functions.
 */
int i2c_switch_reset(enum i2c_switch_reset_value val);

/**
 * @brief Return interrupt status register
 *
 * The MAX7367 interrupt status indicates which of the downstream interrupt
 * lines are asserted. Reading the interrupt status does not clear it; the
 * downstream devices have to de-assert their interrupt lines.
 *
 * @note The only interrupt line connected to anything other than a pull-up
 * is `I2C1_EXP_INT2_L`, and only the EP91A6SQ chips are connected to it.
 *
 * @retval
 * -EIO General input / output error.
 * @retval
 * bitfield where bit 0 is set for INT0, bit 1 set for INT1, etc.
 */
int i2c_switch_get_int_status(void);

#ifdef __cplusplus
}
#endif

#endif
```

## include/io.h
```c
/* SPDX-License-Identifier: BSD-3-Clause
 *
 * Copyright 2021 The Chromium OS Authors. All rights reserved.
 * Use of this source code is governed by a BSD-style license that can be
 * found in the LICENSE file.
 */

#ifndef __IO_H
#define __IO_H

#include <zephyr/kernel.h>
#include <zephyr/drivers/gpio.h>

#ifdef __cplusplus
extern "C" {
#endif

enum gpio_signal {
	power_good_led,
	sd_mux_sel,
	sd_mux_en_l,
	usd_pwr_sel,
	usd_pwr_en,
	usd_cd_det,
	sysmon_sel,
	pwr_en,
	pwr_good,
	boot_mode1,
	boot_mode0,
	por_l_load_l,
	fpga_done,
	fpga_prot,
	fpga_comm0,
	tp126,
	tp125,
	board_version_2,
	board_version_1,
	board_version_0,
	si5338c_int,
	exp_reset,
	exp_irq,
	gp213_it68051p1_ch_sel,
	dp1_ps8468_sw,
	hdmi1_gp213_ch_sel,
	somp1_mode_sel,
	gp213_it68051p0_ch_sel,
	dp2_ps8468_sw,
	hdmi2_gp213_ch_sel,
	somp2_mode_sel,
	dp1_ps8468_rst_l,
	dp2_ps8468_rst_l,
	dp1_hdmi_rst_l,
	dp2_hdmi_rst_l,
	it68051_en,
	it68051p0_pwr_det,
	it68051p1_pwr_det,
	it68051_rst_l,
	gp213_it68051p1_hpd,
	i2c2_int_l,
	dp1_auxp_det,
	dp1_auxn_det,
	dp2_auxp_det,
	dp2_auxn_det,
	hdmi1_pp3300,
	hdmi2_pp3300,
	dp1_mcu_hpd,
	dp2_mcu_hpd,
	dp_in_pwr_en,
	dp1_ps8468_mode,
	dp1_ps8468_cfg0,
	dp1_ps8468_cfg1,
	dp1_ps8468_cfg2,
	dp1_ps8468_cfg3,
	dp1_ps8468_cfg4,
	dp1_ps8468_eq0,
	dp1_ps8468_eq1,
	dp2_ps8468_mode,
	dp2_ps8468_cfg0,
	dp2_ps8468_cfg1,
	dp2_ps8468_cfg2,
	dp2_ps8468_cfg3,
	dp2_ps8468_cfg4,
	dp2_ps8468_eq0,
	dp2_ps8468_eq1,
	dp1_out_sw,
	dp1_out_pd_l,
	dp1_out_mode,
	dp2_out_sw,
	dp2_out_pd_l,
	dp2_out_mode,
	pcie_perst_l,
	pcie_wake_l,
	pcie_rsvd1,
	pcie_rsvd2,
	pcie_rsvd3,
	pcie_rsvd4,
	som_a34,
	som_a21,
	som_a98,
	som_a104,
};

/**
 * @brief Get the current value of a signal.
 *
 * @param signal	Signal to get
 * @return 0 if low, 1 if high.
 */
int gpio_get_level(enum gpio_signal signal);

/**
 * @brief Set the value of a signal.
 *
 * @param signal	Signal to set
 * @param value		New value for signal (0 = low, 1 = high)
 * @return 0 if successful, otherwise errno from gpio_pin_set
 */
int gpio_set_level(enum gpio_signal signal, int value);

/**
 * @brief Return the device pointer of a given GPIO signal.
 *
 * This allows code to use other Zephyr API calls such as configuring
 * for interrupts.
 *
 * @param signal    Signal to name
 * @returns device pointer for the GPIO
 */
const struct device *gpio_get_device(enum gpio_signal signal);

/**
 * Return the pin number of a given GPIO signal.
 *
 * This allows code to use other Zephyr API calls such as configuring
 * for interrupts.
 *
 * @param signal    Signal to name
 * @returns pin number for the GPIO
 */
gpio_pin_t gpio_get_pin(enum gpio_signal signal);

#ifdef __cplusplus
}
#endif

#endif
```

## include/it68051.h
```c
/* SPDX-License-Identifier: BSD-3-Clause
 *
 * Copyright 2020 The ChromiumOS Authors
 * Use of this source code is governed by a BSD-style license that can be
 * found in the LICENSE file.
 *
 * "Public" API for controling the IT68051 HDMI Receiver.
 */

#ifndef __IT68051_H
#define __IT68051_H

#include <zephyr/kernel.h>

#ifdef __cplusplus
extern "C" {
#endif

/*
 * Note that the HDMI/DP ports are connected to the IT68051 as HDMI1/DP1 to
 * IT68051 Port 1, and HDMI2/DP2 are connected to IT68051 Port **zero**.
 */
enum it68051_port { PORT1 = 1, PORT2 = 0 };

enum pixel_mode { MODE_SINGLE = 0, MODE_DUAL = 1 };

enum avi_color_format {
	COLOR_FORMAT_RGB = 0,
	COLOR_FORMAT_YUV422 = 1,
	COLOR_FORMAT_YUV444 = 2,
	COLOR_FORMAT_YUV420 = 3,
	COLOR_FORMAT_BYPASS_CSC = 4
};

enum avi_colorimetry {
	COLORIMETRY_UNKNOWN,
	COLORIMETRY_ITU601 = 1,
	COLORIMETRY_ITU709 = 2,
	COLORIMETRY_EXTEND = 3
};

enum avi_range_type_rgb {
	RGB_RANGE_DEPENDED_ON_VIC = 0,
	RGB_RANGE_LIMIT = 1,
	RGB_RANGE_FULL = 2,
	RGB_RANGE_RESERVE
};

enum avi_range_type_yuv {
	YUV_RANGE_LIMIT = 0,
	YUV_RANGE_FULL = 1,
	YUV_RANGE_RESERVE1,
	YUV_RANGE_RESERVE2
};

enum video_data_path {
	TTL_SDR = 0,
	TTL_DDR,
	TTL_HALF_BUS_DDR,
	TTL_SDR_BTA1004,
	TTL_DDR_BTA1004
};

enum video_sync_mode {
	TTL_SEP_SYNC = 0,
	TTL_EMB_SYNC,
};

/* Details about the video timing */
struct vtiming {
	uint16_t h_active;
	uint16_t v_active;
	uint16_t h_total;
	uint16_t v_total;
	uint32_t pclk;
	uint32_t tmdsclk;
	uint32_t frame_rate;
	uint16_t h_front_porch;
	uint16_t h_sync_width;
	uint16_t h_back_porch;
	uint16_t v_front_porch;
	uint16_t v_sync_width;
	uint16_t v_back_porch;
	uint16_t scan_mode;
	uint16_t v_polarity;
	uint16_t h_polarity;
	uint32_t n;
	uint32_t cts;
};

/* Details about the audio timing */
struct atiming {
	bool aud_3d_on;
	bool mult_aud_on;
	bool hbr_aud;
	bool dsd_aud;

	/* Can be -1 if invalid */
	int8_t aud_ch;

	/* Fs in Hz, except
	 * 0 = "Refer to Stream Header"
	 * -1 = Invalid
	 */
	int32_t aud_fs;
};

/* Details from the AVI Information Frame */
struct aviif {
	enum avi_color_format aviif_input_color_format;
	enum avi_colorimetry aviif_colorimetry;
	enum avi_range_type_rgb aviif_rgb_quantization_range;
	enum avi_range_type_yuv aviif_yuv_quantization_range;
	uint8_t aviif_vic;
	uint8_t aviif_extended_colorimetry;
};

/**
 * @brief Get the chip ID
 *
 * Several functions depend on the specific silicon version to determine
 * which registers to write and what values to write.
 *
 * @return Chip ID byte
 */
uint8_t it68051_get_chip_id(void);

/**
 * @brief Configure how the decoded video is presented on the output bus
 *
 * Configure the data path (SDR or DDR plus variations), whether sync signals
 * are on separate pins or embedded in the data, and the color format
 * (RGB or a couple of YUV options).
 *
 * Based on code in iTE6805_Set_TTL_Video_Path in iTE6805_DRV.c
 *
 * @param video_out_data_path signalling on the TTL lines
 * @param video_sync_mode if sync is separate or embedded
 * @param output_color_format RGB or YUV format, with possible decimation for
 * YUV format
 */
void it68051_set_ttl_video_path(enum video_data_path video_out_data_path,
				enum video_sync_mode video_sync_mode,
				enum avi_color_format output_color_format);

/**
 * @brief Calculate all kinds of data about the input video stream
 *
 * Based on code in iTE6805_Get_VID_Info in iTE6805_DRV.c
 *
 * @param vt pointer to a struct vtiming to fill in
 */
void it68051_get_vid_info(struct vtiming *vt);

/**
 * @brief Calculate all kinds of data about the input audio stream
 *
 * Based on code in iTE6805_Show_AUD_Info in iTE6805_DRV.c
 *
 * @param at pointer to a struct atiming to fill in
 */
void it68051_get_aud_info(struct atiming *at);

/**
 * @brief Get information from the AVI Information Frame
 *
 * @param if pointer to a struct to fill in
 */
void it68051_get_aviif(struct aviif *info);

/**
 * @brief Determine if the TTL outputs are in single- or dual-pixel mode
 *
 * Based on code in iTE6805_Check_Single_Dual_Mode in iTE6805_DRV.c
 *
 * @return MODE_DUAL or MODE_SINGLE to indicate the pixel mode
 */
enum pixel_mode it68051_get_pixel_mode(void);

/**
 * @brief Set the TTL outputs for single- or dual-pixel mode
 *
 * This function sets an internal flag that `it68051_video_output_setting`
 * uses to write the correct value to the register. So this function
 * is not exactly orthogonal to `it68051_get_pixel_mode`.
 *
 * @param mode MODE_DUAL or MODE_SINGLE
 */
void it68051_set_pixel_mode(enum pixel_mode mode);

/**
 * @brief Query if the link status is active
 *
 * This function just returns the internal variable `vid_stable_done`
 * to indicate if we have an established video link on the IT68051.
 *
 * @return bool indicating if the link is active
 */
bool it68051_get_link_active(void);

/**
 * @brief Control whether the video output pins are tristated
 *
 * @param is_tristate true to tristate the pins, false to actively drive them
 *
 * Based on code in iTE6805_Set_Video_Tristate in iTE6805_DRV.c
 */
void it68051_set_video_tristate(bool is_tristate);

/**
 * @brief Control whether the audio output pins are tristated
 *
 * @param is_tristate true to tristate the pins, false to actively drive them
 *
 * Based on code in iTE6805_Set_Audio_Tristate in iTE6805_DRV.c
 */
void it68051_set_audio_tristate(bool is_tristate);

/**
 * @brief Control the HPD (hot plug detect) signals for both ports
 *
 * HDMI uses a HPD (hot plug detect) signal to indicate that a cable is
 * connected. The sink (that's us) has to assert HPD for the source (that's
 * the Chromebook) to recognize a connected sink, query the EDID, and then
 * start sending data to it.
 *
 * Based on code in iTE6805_Set_HPD_Ctrl and iTE6805_Port_Select_Body in
 * iTE6805_DRV.c
 *
 * b/201944380, when setting HPD low, also pulse the EXT_RESET_N signal
 * for the MCDP2900 DisplayPort to HDMI converter chip. This chip keeps its
 * HPD output asserted, even when the HPD input is de-asserted, and the only
 * way we've found to get HPD to de-assert is to reset the chip. The MCDP2900
 * datasheet is unclear on how long the external reset pulse needs to be
 * (rev H datasheet, figure 4), so we're using a 2ms delay between asserting
 * the reset and releasing it.
 *
 * @param port PORT1 or PORT2
 * @param hpd_state false to de-assert, true to assert
 */
void it68051_set_hpd(enum it68051_port port, bool hpd_state);

/**
 * @brief Query the HPD (hot plug detect) signals for both ports
 *
 * Determine if we are driving HPD on the port.
 *
 * @param port PORT1 or PORT2
 * @return Whether HPD is being asserted
 */
bool it68051_get_hpd(enum it68051_port port);

/**
 * @brief Select which port the HDMI receiver is listening to
 *
 * The IT68051 has two input ports, so we need to tell it which port it
 * should be decoding.
 *
 * Based on code in iTE6805_Port_Select in iTE6805_SYS.c
 *
 * @param port PORT1 or PORT2
 */
void it68051_port_select(enum it68051_port port);

/**
 * @brief Determine  which port the HDMI receiver is listening to
 *
 * @return PORT1 or PORT2
 */
enum it68051_port it68051_get_selected_port(void);

/**
 * @brief Determine if the PWR_DET signal is active for a port
 *
 * Note that since these are controlled by the STM32, they will almost
 * always be active. "almost always"
 * Also, with an HDMI connector, the signal is 5V, but the R0PWR5V and R1PWR5V
 * pins are 3.3V logic/5V tolerant, so the 3.3V from the STM32 works just
 * fine.
 *
 * Based on code in iTE6805_Check_5V_State in iTE6805_DRV.c
 *
 * @param port Port number to check - these are the external port numbers,
 * so PORT2 and PORT1
 * @return true if the PWR_DET input is active, false otherwise
 */
bool it68051_is_5v_active(enum it68051_port port);

/**
 * @brief Mute the audio and video from the HDMI
 *
 * Based on code in iTE6805_Set_AVMute in iTE6805_DRV.c
 *
 * @param mute true to mute, false to unmute
 */
void it68051_set_av_mute(bool mute);

/**
 * @brief Determine if the HDMI A/V inputs are muted
 *
 * Based on code in iTE6805_Check_AVMute in iTE6805_DRV.c
 *
 * @return true if muted, false if not
 */
bool it68051_check_av_mute(void);

/**
 * @brief Reset the video logic and clear the vid-stable interrupt
 *
 * Based on code in iTE6805_Reset_Video_Logic in iTE6805_DRV.c
 */
void it68051_reset_video_logic(void);

/**
 * @brief Reset the audio logic
 *
 * Based on code in iTE6805_Reset_Audio_Logic in iTE6805_DRV.c
 */
void it68051_reset_audio_logic(void);

/**
 * @brief Take exclusive control of the IT68051
 *
 * This function locks a mutex so that other threads (who also use this
 * function) will be blocked until the first one is done.
 */
void it68051_lock(void);

/**
 * @brief Release exclusive control of the IT68051
 *
 * Unlock the mutex and let other threads that use the IT68051 run.
 */
void it68051_unlock(void);

#ifdef __cplusplus
}
#endif

#endif
```

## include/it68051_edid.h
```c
/* SPDX-License-Identifier: BSD-3-Clause
 *
 * Copyright 2020 The ChromiumOS Authors
 * Use of this source code is governed by a BSD-style license that can be
 * found in the LICENSE file.
 *
 * Based on code in iTE6805_EDID.[ch] and iTE6805_EDID_Table.h
 *  Copyright (c) 2023 ITE Tech. Inc.
 *  SPDX-License-Identifier: BSD-3-Clause
 *
 * Functions for managing the IT68051 EDID RAM.
 */

#ifndef __IT68051_EDID_H
#define __IT68051_EDID_H

#include <zephyr/kernel.h>

#ifdef __cplusplus
extern "C" {
#endif

/*
 * Number of EDIDs that are available to select from the shell.
 */
#define EDID_COUNT 17

/*
 * Default EDID
 *
 * Be explicit about which EDID we want to use at start-up, instead of
 * using a magic number in the code.
 */
#define DEFAULT_EDID_IDX 8

/**
 * @brief Initialize the EDID RAM
 *
 * Based on code in iTE6805_EDID_Init in iTE6805_EDID.c
 */
void it68051_edid_init(void);

/**
 * @brief Set the active EDID
 *
 * The internal function `it68051_edid_init_ram` uses an index into
 * a table of EDIDs to determine which EDID to load into the IT68051.
 * This function changes that index. The caller is responsible for
 * turning off HPD, setting the index, calling `it68051_edid_init`
 * again, and then turning on HPD.
 *
 * @param idx Index into the EDID table for which one to select
 * @retval 0 success
 * @retval -EINVAL index was outside the range of the table
 */
int it68051_edid_select(int idx);

/**
 * @brief Initialize the EDID RAM block and related registers
 *
 * Based on code in iTE6805_EDID_RAMInitial in iTE6805_EDID.c
 *
 * @param p_edid pointer to 256-byte EDID data
 */
void it68051_edid_write_block(const uint8_t *p_edid);

/**
 * @brief Read the EDID RAM block
 *
 * Note that the caller is responsible for making sure that p_edid points
 * to at least 256 bytes of memory!
 *
 * @param p_edid pointer to where to put 256-byte EDID data
 */
void it68051_edid_read_block(uint8_t *p_edid);

#ifdef __cplusplus
}
#endif

#endif
```

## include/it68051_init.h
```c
/* SPDX-License-Identifier: BSD-3-Clause
 *
 * Copyright 2020 The ChromiumOS Authors
 * Use of this source code is governed by a BSD-style license that can be
 * found in the LICENSE file.
 *
 * Based on code in iTE6805_DRV.c,  iTE6805_I2C_RDWR.h, and iTE6805_INI_Table.h
 *  Copyright (c) 2023 ITE Tech. Inc.
 *  SPDX-License-Identifier: BSD-3-Clause
 */

#ifndef __IT68051_INIT_H
#define __IT68051_INIT_H

#include <zephyr/kernel.h>

#ifdef __cplusplus
extern "C" {
#endif

/**
 * @brief Initialize the IT68051 with data provided by ITE.
 *
 * Based on code in iTE6805_Init_fsm in iTE6805_DRV.c
 *
 * @retval 0 success
 * @retval -ENODEV failed to get the I2C device to access the IT68051
 */
int it68051_init(void);

/**
 * @brief Get the RCLK value that it68051_oclk_cal() computed.
 *
 * @return RCLK value
 */
uint32_t it68051_get_rclk_value(void);

#ifdef __cplusplus
}
#endif

#endif
```
